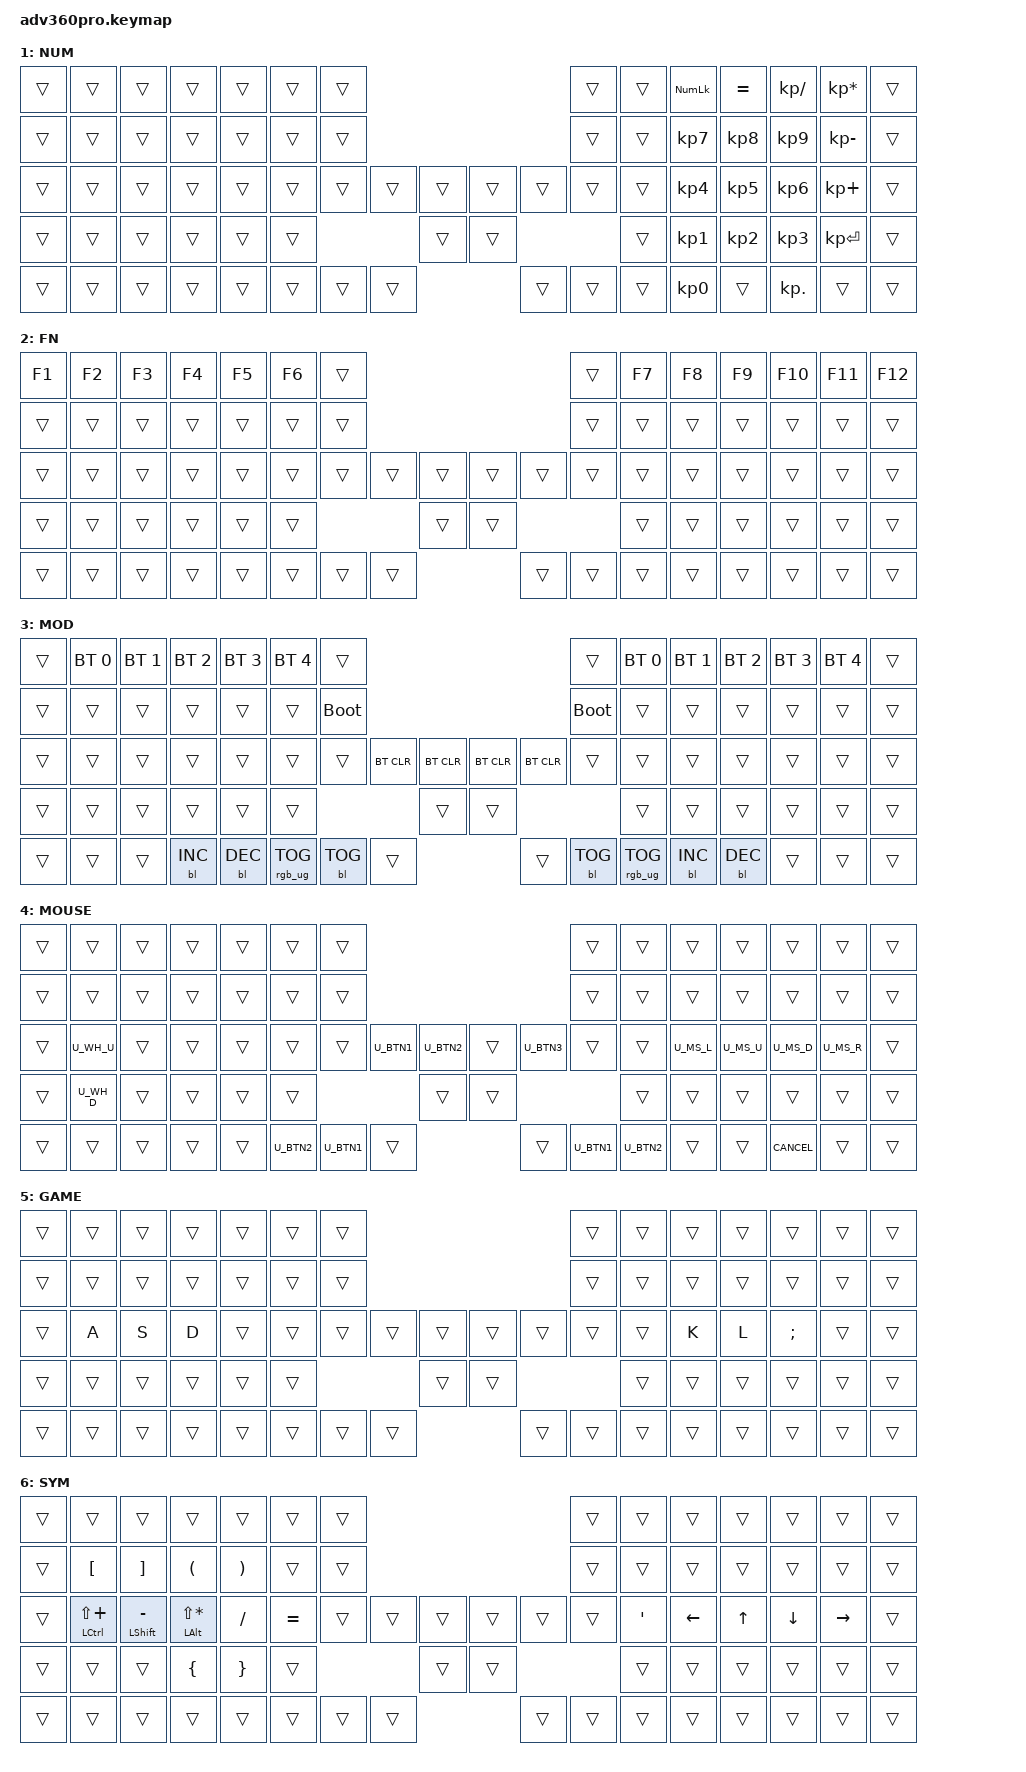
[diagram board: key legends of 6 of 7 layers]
#include <behaviors.dtsi>
#include <behaviors/num_word.dtsi> // Requires auto-layer module.
#include <dt-bindings/zmk/keys.h>
#include <dt-bindings/zmk/bt.h>
#include <dt-bindings/zmk/rgb.h>
//#include <dt-bindings/zmk/stp.h>
//#define STP_BAT 0
#include <dt-bindings/zmk/backlight.h>
#include <dt-bindings/zmk/pointing.h>

#include "zmk-helpers/helper.h"



#define XXX &none
#define ___ &trans

#define DEF 0
#define NUM 1
#define FN 2
#define MOD 3
#define MOUSE 4
#define GAME 5
#define SYM 6

#include "base_defs.keymap"


//#include <input/processors.dtsi>
//#include <zephyr/dt-bindings/input/input-event-codes.h>
/ {
    behaviors {
      //#include "macros.dtsi" //macros as of now unused
      #include "mouse.dtsi"
      //#include "version.dtsi" //unused as of now
      
      hm: homerow_mods {
          compatible = "zmk,behavior-hold-tap";
          label = "HOMEROW_MODS";
          #binding-cells = <2>;
          tapping-term-ms = <200>;
          quick_tap_ms = <175>;
          flavor = "tap-preferred";
          bindings = <&kp>, <&kp>;
      };
    };
  //chosen { zmk,matrix_transform = &urobs_transform; };
  keymap {
    compatible = "zmk,keymap";
    default_layer {
      display-name = "BASE";
      bindings = <
        &kp EQUAL   &kp N1          &kp N2          &kp N3      &kp N4      &kp N5      SMART_NUM                                                         &mo MOD     &kp N6      &kp N7      &kp N8          &kp N9          &kp N0                  &kp MINUS
        &kp ESC     &kp Q           &kp W           &kp E       &kp R       &kp T       XXX                                                               XXX         &kp Y       &kp U       &kp I           &kp O           &kp P                   &kp SQT
        &kp TAB     &hml LCTRL A    &hml LSHIFT S   &hml RALT D &kp F       &kp G       XXX         &kp LCTRL   &kp LALT      &kp LGUI      &kp RCTRL     &tog GAME   &kp H       &kp J       &hmr RALT K     &hmr RSHIFT L   &hmr RCTRL SEMICOLON    &kp BACKSLASH
        &kp LSHFT   &kp Z           &kp X           &kp C       &kp V       &kp B                               &mo SYM       &mo SYM                                 &kp N       &kp M       &kp COMMA       &kp DOT         &kp FSLH                &kp RSHFT
        &mo FN      &kp GRAVE       XXX             &kp LEFT    &kp RIGHT               &kp DEL     &kp SPACE     &td0        &smart_mouse  &kp ENTER                             &kp BSPC    &kp UP          &kp DOWN        XXX                     &mo FN
      >;
    };
    num {
      display-name = "NUM";
      bindings = <
        ___         ___             ___             ___         ___         ___         ___                           ___         ___         &kp KP_NUM  &kp EQUAL       &kp KP_DIVIDE   &kp KP_MULTIPLY         ___
        ___         ___             ___             ___         ___         ___         ___                           ___         ___         &kp KP_N7   &kp KP_N8       &kp KP_N9       &kp KP_MINUS            ___
        ___         ___             ___             ___         ___         ___         ___     ___ ___   ___ ___     ___         ___         &kp KP_N4   &kp KP_N5       &kp KP_N6       &kp KP_PLUS             ___
        ___         ___             ___             ___         ___         ___                     ___   ___                     ___         &kp KP_N1   &kp KP_N2       &kp KP_N3       &kp KP_ENTER            ___
        ___         ___             ___             ___         ___                         ___ ___ ___   ___ ___ ___                         &kp KP_N0   ___             &kp KP_DOT      ___                     ___    
      >;
    };
    fn {
      display-name = "FN";
      bindings = <
        &kp F1      &kp F2          &kp F3          &kp F4      &kp F5      &kp F6      ___                           ___         &kp F7      &kp F8      &kp F9          &kp F10         &kp F11                 &kp F12
        ___         ___             ___             ___         ___         ___         ___                           ___         ___         ___         ___             ___             ___                     ___
        ___         ___             ___             ___         ___         ___         ___     ___ ___   ___ ___     ___         ___         ___         ___             ___             ___                     ___
        ___         ___             ___             ___         ___         ___                     ___   ___                     ___         ___         ___             ___             ___                     ___
        ___         ___             ___             ___         ___                         ___ ___ ___   ___ ___ ___                         ___         ___             ___             ___                     ___
      >;
    };
    mod {
      display-name = "MOD";
      bindings = <
        ___         &bt BT_SEL 0    &bt BT_SEL 1    &bt BT_SEL 2    &bt BT_SEL 3    &bt BT_SEL 4    ___                                                                               ___                     &bt BT_SEL 0    &bt BT_SEL 1     &bt BT_SEL 2 &bt BT_SEL 3 &bt BT_SEL 4 ___
        ___         ___             ___             ___             ___             ___             &bootloader                                                                       &bootloader             ___             ___              ___          ___          ___          ___
        ___         ___             ___             ___             ___             ___             ___               &bt BT_CLR    &bt BT_CLR  &bt BT_CLR &bt BT_CLR                 ___                     ___             ___              ___          ___          ___          ___
        ___         ___             ___             ___             ___             ___                                             ___           ___                                                   ___             ___              ___          ___          ___          ___
        ___         ___             ___             &bl BL_INC      &bl BL_DEC                        &rgb_ug RGB_TOG &bl BL_TOG    ___           ___         &bl BL_TOG      &rgb_ug RGB_TOG                           &bl BL_INC       &bl BL_DEC   ___          ___          ___
      >;
    };
    mouse {
      display-name = "MOUSE"; 
      bindings = <
        ___       ___       ___       ___       ___       ___       ___                                                 ___       ___       ___       ___       ___       ___       ___
        ___       ___       ___       ___       ___       ___       ___                                                 ___       ___       ___       ___       ___       ___       ___
        ___       U_WH_U    ___       ___       ___       ___       ___               U_BTN1 U_BTN2    ___ U_BTN3       ___       ___       U_MS_L    U_MS_U    U_MS_D    U_MS_R    ___
        ___       U_WH_D    ___       ___       ___       ___                                ___       ___                        ___       ___       ___       ___       ___       ___
        ___       ___       ___       ___       ___                            U_BTN2 U_BTN1 ___       ___ U_BTN1 U_BTN2                    ___       ___       CANCEL    ___       ___                                                             
    >;
    };


    game { 
      display-name = "GAME";    
      bindings = <
        ___       ___       ___       ___       ___       ___       ___                            ___       ___       ___       ___       ___             ___       ___
        ___       ___       ___       ___       ___       ___       ___                            ___       ___       ___       ___       ___             ___       ___
        ___       &kp A     &kp S     &kp D     ___       ___       ___     ___ ___    ___ ___     ___       ___       &kp K     &kp L     &kp SEMICOLON   ___       ___
        ___       ___       ___       ___       ___       ___                   ___    ___                   ___       ___       ___       ___             ___       ___
        ___       ___       ___       ___       ___                     ___ ___ ___    ___ ___ ___                     ___       ___       ___             ___       ___                                                             
    >;
    };
    
    sym { 
      display-name = "SYM";    
      bindings = <
        ___       ___                 ___               ___                     ___                   ___       ___                            ___       ___       ___       ___       ___       ___       ___
        ___       &kp LEFT_BRACKET    &kp RIGHT_BRACKET &kp LEFT_PARENTHESIS    &kp RIGHT_PARENTHESIS ___       ___                            ___       ___       ___       ___       ___       ___       ___
        ___       &hml LCTRL LS(PLUS) &hml LSHIFT MINUS &hml LALT LS(ASTERISK)  &kp SLASH             &kp EQUAL ___     ___ ___    ___ ___     ___       &kp SQT   &kp LEFT  &kp UP    &kp DOWN  &kp RIGHT ___
        ___       ___                 ___               &kp LEFT_BRACE          &kp RIGHT_BRACE       ___                   ___    ___                   ___       ___       ___       ___       ___       ___
        ___       ___                 ___               ___                     ___                                 ___ ___ ___    ___ ___ ___                     ___       ___       ___       ___       ___                                                             
    >;
    };
    extra2 {
      display-name = "Purple";    
      status = "reserved";
    };

    extra3 { 
      display-name = "Cyan";    
      status = "reserved";
    };

    extra4 { 
      display-name = "Yellow";    
      status = "reserved";
    };
  };
};
